# BE-U1000 register map
Vendor: BAIKAL ELECTRONICS, JSC; File version: 1.0
CPU: RISC-V r0p0, little endian, no MPU, no FPU, 3 interrupt priority bits
Registers are 32-bit, read-write, reset 0x0 unless marked. A register's access mark holds for its fields unless they carry their own. Offsets are from the block's base; [hi:lo] are bit positions; {n}, {i} and the like mark numbered series.

## CRU — Control Registers Unit
Base 0x14000000
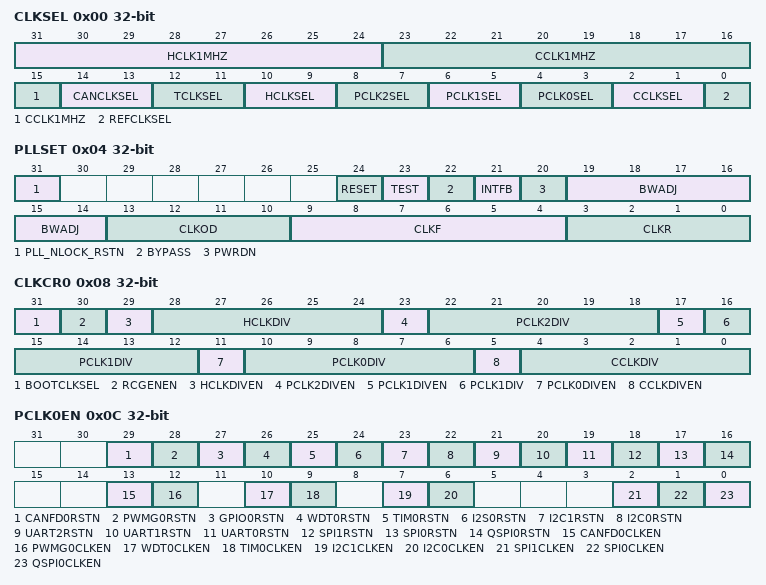
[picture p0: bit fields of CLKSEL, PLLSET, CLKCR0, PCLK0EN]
0x00 CLKSEL — Clock select control
  [31:24] HCLK1MHZ — HCLK 1MHz pulse generator prescaler
  [23:15] CCLK1MHZ — CCLK 1MHz pulse generator prescaler
  [14:13] CANCLKSEL — CANx2 clock (CANx2CLK) source select
    0=C0 (C0 used as CANx2 clock (CANx2CLK) source); 1=PLL (PLL used as CANx2 clock (CANx2CLK) source); 2=C1 (C1 used as CANx2 clock (CANx2CLK) source)
  [12:11] TCLKSEL — TRACE clock (TRACECLK) source select
    0=C0 (C0 used as TRACE clock (TCLK) source); 1=PLL (PLL used as TRACE clock (TCLK) source); 2=C1 (C1 used as TRACE clock (TCLK) source)
  [10:9] HCLKSEL — AHB domain clock (HCLK) source select
    0=C0 (C0 used as AHB domain clock (HCLK) source); 1=PLL (PLL used as AHB domain clock (HCLK) source); 2=C1 (C1 used as AHB domain clock (HCLK) source)
  [8:7] PCLK2SEL — APB2 domain clock (PCLK2) source select
    0=C0 (C0 used as APB2 domain clock (PCLK2) source); 1=PLL (PLL used as APB2 domain clock (PCLK2) source); 2=C1 (C1 used as APB2 domain clock (PCLK2) source)
  [6:5] PCLK1SEL — APB1 domain clock (PCLK1) source select
    0=C0 (C0 used as APB1 domain clock (PCLK1) source); 1=PLL (PLL used as APB1 domain clock (PCLK1) source); 2=C1 (C1 used as APB1 domain clock (PCLK1) source)
  [4:3] PCLK0SEL — APB0 domain clock (PCLK0) source select
    0=C0 (C0 used as APB0 domain clock (PCLK0) source); 1=PLL (PLL used as APB0 domain clock (PCLK0) source); 2=C1 (C1 used as APB0 domain clock (PCLK0) source)
  [2:1] CCLKSEL — AXI domain clock (CCLK) source select
    0=C0 (C0 used as AXI domain clock (CCLK) source); 1=PLL (PLL used as AXI domain clock (CCLK) source); 2=C1 (C1 used as AXI domain clock (CCLK) source)
  [0] REFCLKSEL — PLL clock source select
    0=C0 (C0 selected as PLL clock source); 1=C1 (C1 selected as PLL clock source)
0x04 PLLSET — PLL configuration set
  [31] PLL_NLOCK_RSTN — PLL_NLOCK flag reset
    0=DISABLE; 1=ENABLE
  [24] RESET — PLL reset
    0=DISABLE; 1=ENABLE
  [23] TEST — PLL reference to counters to output bypass
    0=DISABLE; 1=ENABLE
  [22] BYPASS — PLL reference to output bypass
    0=DISABLE; 1=ENABLE
  [21] INTFB — PLL internal feedback path select
    0=DISABLE; 1=ENABLE
  [20] PWRDN — PLL power down
    0=DISABLE; 1=ENABLE
  [19:14] BWADJ — PLL bandwidth divider (NB) value
  [13:10] CLKOD — PLL post VCO divider (OD) value
  [9:4] CLKF — PLL multiplication factor (NF) value
  [3:0] CLKR — PLL reference divider (NR) value
0x08 CLKCR0 — Clock domains select control 0
  [31] BOOTCLKSEL — Boot clock source select
    0=DISABLE; 1=ENABLE
  [30] RCGENEN — RC generator enable
    0=DISABLE; 1=ENABLE
  [29] HCLKDIVEN — HCLK divider enable
    0=DISABLE; 1=ENABLE
  [28:24] HCLKDIV — HCLK divider
    0=DIV1 (HCLK not divided); 2=DIV2 (HCLK divided by 2); 4=DIV3 (HCLK divided by 3); 6=DIV4 (HCLK divided by 4); 8=DIV5 (HCLK divided by 5); 10=DIV6 (HCLK divided by 6); 12=DIV7 (HCLK divided by 7); 14=DIV8 (HCLK divided by 8); 16=DIV9 (HCLK divided by 9); 18=DIV10 (HCLK divided by 10); 20=DIV11 (HCLK divided by 11); 22=DIV12 (HCLK divided by 12); 24=DIV13 (HCLK divided by 13); 26=DIV14 (HCLK divided by 14); 28=DIV15 (HCLK divided by 15); 30=DIV16 (HCLK divided by 16); 1=DIV1_5 (HCLK divided by 1.5); 3=DIV2_5 (HCLK divided by 2.5); 5=DIV3_5 (HCLK divided by 3.5); 7=DIV4_5 (HCLK divided by 4.5); 9=DIV5_5 (HCLK divided by 5.5); 11=DIV6_5 (HCLK divided by 6.5); 13=DIV7_5 (HCLK divided by 7.5); 15=DIV8_5 (HCLK divided by 8.5); 17=DIV9_5 (HCLK divided by 9.5); 19=DIV10_5 (HCLK divided by 10.5); 21=DIV11_5 (HCLK divided by 11.5); 23=DIV12_5 (HCLK divided by 12.5); 25=DIV13_5 (HCLK divided by 13.5); 27=DIV14_5 (HCLK divided by 14.5); 29=DIV15_5 (HCLK divided by 15.5)
  [23] PCLK2DIVEN — PCLK2 divider enable
    0=DISABLE; 1=ENABLE
  [22:18] PCLK2DIV — PCLK2 divider
    0=DIV1 (PCLK2 not divided); 2=DIV2 (PCLK2 divided by 2); 4=DIV3 (PCLK2 divided by 3); 6=DIV4 (PCLK2 divided by 4); 8=DIV5 (PCLK2 divided by 5); 10=DIV6 (PCLK2 divided by 6); 12=DIV7 (PCLK2 divided by 7); 14=DIV8 (PCLK2 divided by 8); 16=DIV9 (PCLK2 divided by 9); 18=DIV10 (PCLK2 divided by 10); 20=DIV11 (PCLK2 divided by 11); 22=DIV12 (PCLK2 divided by 12); 24=DIV13 (PCLK2 divided by 13); 26=DIV14 (PCLK2 divided by 14); 28=DIV15 (PCLK2 divided by 15); 30=DIV16 (PCLK2 divided by 16); 1=DIV1_5 (PCLK2 divided by 1.5); 3=DIV2_5 (PCLK2 divided by 2.5); 5=DIV3_5 (PCLK2 divided by 3.5); 7=DIV4_5 (PCLK2 divided by 4.5); 9=DIV5_5 (PCLK2 divided by 5.5); 11=DIV6_5 (PCLK2 divided by 6.5); 13=DIV7_5 (PCLK2 divided by 7.5); 15=DIV8_5 (PCLK2 divided by 8.5); 17=DIV9_5 (PCLK2 divided by 9.5); 19=DIV10_5 (PCLK2 divided by 10.5); 21=DIV11_5 (PCLK2 divided by 11.5); 23=DIV12_5 (PCLK2 divided by 12.5); 25=DIV13_5 (PCLK2 divided by 13.5); 27=DIV14_5 (PCLK2 divided by 14.5); 29=DIV15_5 (PCLK2 divided by 15.5)
  [17] PCLK1DIVEN — PCLK1 divider enable
    0=DISABLE; 1=ENABLE
  [16:12] PCLK1DIV — PCLK1 divider
    0=DIV1 (PCLK1 not divided); 2=DIV2 (PCLK1 divided by 2); 4=DIV3 (PCLK1 divided by 3); 6=DIV4 (PCLK1 divided by 4); 8=DIV5 (PCLK1 divided by 5); 10=DIV6 (PCLK1 divided by 6); 12=DIV7 (PCLK1 divided by 7); 14=DIV8 (PCLK1 divided by 8); 16=DIV9 (PCLK1 divided by 9); 18=DIV10 (PCLK1 divided by 10); 20=DIV11 (PCLK1 divided by 11); 22=DIV12 (PCLK1 divided by 12); 24=DIV13 (PCLK1 divided by 13); 26=DIV14 (PCLK1 divided by 14); 28=DIV15 (PCLK1 divided by 15); 30=DIV16 (PCLK1 divided by 16); 1=DIV1_5 (PCLK1 divided by 1.5); 3=DIV2_5 (PCLK1 divided by 2.5); 5=DIV3_5 (PCLK1 divided by 3.5); 7=DIV4_5 (PCLK1 divided by 4.5); 9=DIV5_5 (PCLK1 divided by 5.5); 11=DIV6_5 (PCLK1 divided by 6.5); 13=DIV7_5 (PCLK1 divided by 7.5); 15=DIV8_5 (PCLK1 divided by 8.5); 17=DIV9_5 (PCLK1 divided by 9.5); 19=DIV10_5 (PCLK1 divided by 10.5); 21=DIV11_5 (PCLK1 divided by 11.5); 23=DIV12_5 (PCLK1 divided by 12.5); 25=DIV13_5 (PCLK1 divided by 13.5); 27=DIV14_5 (PCLK1 divided by 14.5); 29=DIV15_5 (PCLK1 divided by 15.5)
  [11] PCLK0DIVEN — PCLK0 divider enable
    0=DISABLE; 1=ENABLE
  [10:6] PCLK0DIV — PCLK0 divider
    0=DIV1 (PCLK0 not divided); 2=DIV2 (PCLK0 divided by 2); 4=DIV3 (PCLK0 divided by 3); 6=DIV4 (PCLK0 divided by 4); 8=DIV5 (PCLK0 divided by 5); 10=DIV6 (PCLK0 divided by 6); 12=DIV7 (PCLK0 divided by 7); 14=DIV8 (PCLK0 divided by 8); 16=DIV9 (PCLK0 divided by 9); 18=DIV10 (PCLK0 divided by 10); 20=DIV11 (PCLK0 divided by 11); 22=DIV12 (PCLK0 divided by 12); 24=DIV13 (PCLK0 divided by 13); 26=DIV14 (PCLK0 divided by 14); 28=DIV15 (PCLK0 divided by 15); 30=DIV16 (PCLK0 divided by 16); 1=DIV1_5 (PCLK0 divided by 1.5); 3=DIV2_5 (PCLK0 divided by 2.5); 5=DIV3_5 (PCLK0 divided by 3.5); 7=DIV4_5 (PCLK0 divided by 4.5); 9=DIV5_5 (PCLK0 divided by 5.5); 11=DIV6_5 (PCLK0 divided by 6.5); 13=DIV7_5 (PCLK0 divided by 7.5); 15=DIV8_5 (PCLK0 divided by 8.5); 17=DIV9_5 (PCLK0 divided by 9.5); 19=DIV10_5 (PCLK0 divided by 10.5); 21=DIV11_5 (PCLK0 divided by 11.5); 23=DIV12_5 (PCLK0 divided by 12.5); 25=DIV13_5 (PCLK0 divided by 13.5); 27=DIV14_5 (PCLK0 divided by 14.5); 29=DIV15_5 (PCLK0 divided by 15.5)
  [5] CCLKDIVEN — CCLK divider enable
    0=DISABLE; 1=ENABLE
  [4:0] CCLKDIV — CCLK divider
    0=DIV1 (CCLK not divided); 2=DIV2 (CCLK divided by 2); 4=DIV3 (CCLK divided by 3); 6=DIV4 (CCLK divided by 4); 8=DIV5 (CCLK divided by 5); 10=DIV6 (CCLK divided by 6); 12=DIV7 (CCLK divided by 7); 14=DIV8 (CCLK divided by 8); 16=DIV9 (CCLK divided by 9); 18=DIV10 (CCLK divided by 10); 20=DIV11 (CCLK divided by 11); 22=DIV12 (CCLK divided by 12); 24=DIV13 (CCLK divided by 13); 26=DIV14 (CCLK divided by 14); 28=DIV15 (CCLK divided by 15); 30=DIV16 (CCLK divided by 16); 1=DIV1_5 (CCLK divided by 1.5); 3=DIV2_5 (CCLK divided by 2.5); 5=DIV3_5 (CCLK divided by 3.5); 7=DIV4_5 (CCLK divided by 4.5); 9=DIV5_5 (CCLK divided by 5.5); 11=DIV6_5 (CCLK divided by 6.5); 13=DIV7_5 (CCLK divided by 7.5); 15=DIV8_5 (CCLK divided by 8.5); 17=DIV9_5 (CCLK divided by 9.5); 19=DIV10_5 (CCLK divided by 10.5); 21=DIV11_5 (CCLK divided by 11.5); 23=DIV12_5 (CCLK divided by 12.5); 25=DIV13_5 (CCLK divided by 13.5); 27=DIV14_5 (CCLK divided by 14.5); 29=DIV15_5 (CCLK divided by 15.5)
0x0C PCLK0EN — APB0 domain clock gating control
  [all] fields
    0=DISABLE; 1=ENABLE
  [29] CANFD0RSTN — CANFD0 reset
  [28] PWMG0RSTN — PWMG0 reset
  [27] GPIO0RSTN — GPIO0 reset
  [26] WDT0RSTN — WDT0 reset
  [25] TIM0RSTN — TIM0 reset
  [24] I2S0RSTN — I2S0 reset
  [23] I2C1RSTN — I2C1 reset
  [22] I2C0RSTN — I2C0 reset
  [21] UART2RSTN — UART2 reset
  [20] UART1RSTN — UART1 reset
  [19] UART0RSTN — UART0 reset
  [18] SPI1RSTN — SPI1 reset
  [17] SPI0RSTN — SPI0 reset
  [16] QSPI0RSTN — QSPI0 reset
  [13] CANFD0CLKEN — CANFD0 clock enable
  [12] PWMG0CLKEN — PWMG0 clock enable
  [10] WDT0CLKEN — WDT0 clock enable
  [9] TIM0CLKEN — TIM0 clock enable
  [7] I2C1CLKEN — I2C1 clock enable
  [6] I2C0CLKEN — I2C0 clock enable
  [2] SPI1CLKEN — SPI1 clock enable
  [1] SPI0CLKEN — SPI0 clock enable
  [0] QSPI0CLKEN — QSPI0 clock enable
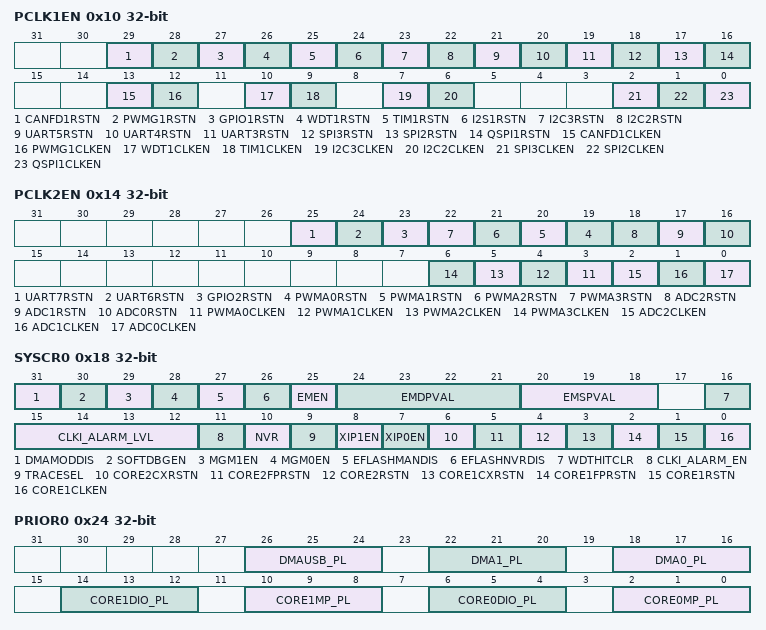
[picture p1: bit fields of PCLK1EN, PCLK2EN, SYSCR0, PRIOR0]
0x10 PCLK1EN — APB1 domain clock gating control
  [all] fields
    0=DISABLE; 1=ENABLE
  [29] CANFD1RSTN — CANFD1 reset
  [28] PWMG1RSTN — PWMG1 reset
  [27] GPIO1RSTN — GPIO1 reset
  [26] WDT1RSTN — WDT1 reset
  [25] TIM1RSTN — TIM1 reset
  [24] I2S1RSTN — I2S1 reset
  [23] I2C3RSTN — I2C3 reset
  [22] I2C2RSTN — I2C2 reset
  [21] UART5RSTN — UART5 reset
  [20] UART4RSTN — UART4 reset
  [19] UART3RSTN — UART3 reset
  [18] SPI3RSTN — SPI3 reset
  [17] SPI2RSTN — SPI2 reset
  [16] QSPI1RSTN — QSPI1 reset
  [13] CANFD1CLKEN — CANFD1 clock enable
  [12] PWMG1CLKEN — PWMG1 clock enable
  [10] WDT1CLKEN — WDT1 clock enable
  [9] TIM1CLKEN — TIM1 clock enable
  [7] I2C3CLKEN — I2C3 clock enable
  [6] I2C2CLKEN — I2C2 clock enable
  [2] SPI3CLKEN — SPI3 clock enable
  [1] SPI2CLKEN — SPI2 clock enable
  [0] QSPI1CLKEN — QSPI1 clock enable
0x14 PCLK2EN — APB2 domain clock gating control
  [all] fields
    0=DISABLE; 1=ENABLE
  [25] UART7RSTN — UART7 reset
  [24] UART6RSTN — UART6 reset
  [23] GPIO2RSTN — GPIO2 reset
  [n+19] PWMA{n}RSTN (n=0..3) — PWMA{n} reset
  [18] ADC2RSTN — ADC2 reset
  [17] ADC1RSTN — ADC1 reset
  [16] ADC0RSTN — ADC0 reset
  [n+3] PWMA{n}CLKEN (n=0..3) — PWMA{n} clock enable
  [2] ADC2CLKEN — ADC2 clock enable
  [1] ADC1CLKEN — ADC1 clock enable
  [0] ADC0CLKEN — ADC0 clock enable
0x18 SYSCR0 — System resource control 0
  [31] DMAMODDIS — Disable write to EFLASH in DMA mode
    0=DISABLE; 1=ENABLE
  [30] SOFTDBGEN — Enable CORE0 and CORE1 software debug
    0=DISABLE; 1=ENABLE
  [29] MGM1EN — MAGMA1 command decryptor enable
    0=DISABLE; 1=ENABLE
  [28] MGM0EN — MAGMA0 command decryptor enable
    0=DISABLE; 1=ENABLE
  [27] EFLASHMANDIS — Disable EFLASH access in manual mode
    0=DISABLE; 1=ENABLE
  [26] EFLASHNVRDIS — Disable EFLASH NVR access
    0=DISABLE; 1=ENABLE
  [25] EMEN — Memory parameters adjustment enable
    0=DISABLE; 1=ENABLE
  [24:21] EMDPVAL — Dual-port memory parameter value
  [20:18] EMSPVAL — Single-port memory parameter value
  [16] WDTHITCLR — Clear WDTHIT flag
    0=DISABLE; 1=ENABLE
  [15:12] CLKI_ALARM_LVL — CLKI monitor threshold
    {v}=CLKI monitor threshold level {v} (v=0..15)
  [11] CLKI_ALARM_EN — CLKI monitor enable
    0=DISABLE; 1=ENABLE
  [10] NVR — EFLASH NVR access enable
    0=DISABLE; 1=ENABLE
  [9] TRACESEL — Select core to trace
    0=CORE0 (Connect Core 0 to trace module); 1=CORE1 (Connect Core 1 to trace module)
  [8] XIP1EN — QSPI1 XIP mode enable
    0=DISABLE; 1=ENABLE
  [7] XIP0EN — QSPI0 XIP mode enable
    0=DISABLE; 1=ENABLE
  [6] CORE2CXRSTN — Core 2 processor complex reset
    0=DISABLE; 1=ENABLE
  [5] CORE2FPRSTN — Core 2 TCM arbitrator reset
    0=DISABLE; 1=ENABLE
  [4] CORE2RSTN — Core 2 reset
    0=DISABLE; 1=ENABLE
  [3] CORE1CXRSTN — Core 1 processor complex reset
    0=DISABLE; 1=ENABLE
  [2] CORE1FPRSTN — Core 1 TCM arbitrator reset
    0=DISABLE; 1=ENABLE
  [1] CORE1RSTN — Core 1 reset
    0=DISABLE; 1=ENABLE
  [0] CORE1CLKEN — Core 1 clock enable
    0=DISABLE; 1=ENABLE
0x1C SYSCR1 — System resource control 1
  [31:0] CORE1RSTVEC — Core 1 reset vector address
0x20 SYSCR2 — System resource control 2
  [31:0] CORE2RSTVEC — Core 2 reset vector address
0x24 PRIOR0 — AXI masters priority control
  [26:24] DMAUSB_PL — USB DMA AXI Interconnect priority level
  [22:20] DMA1_PL — DMA1 AXI Interconnect priority level
  [18:16] DMA0_PL — DMA0 AXI Interconnect priority level
  [14:12] CORE1DIO_PL — DIO Core1 AXI Interconnect priority level
  [10:8] CORE1MP_PL — MP Core1 AXI Interconnect priority level
  [6:4] CORE0DIO_PL — DIO Core0 AXI Interconnect priority level
  [2:0] CORE0MP_PL — MP Core0 AXI Interconnect priority level
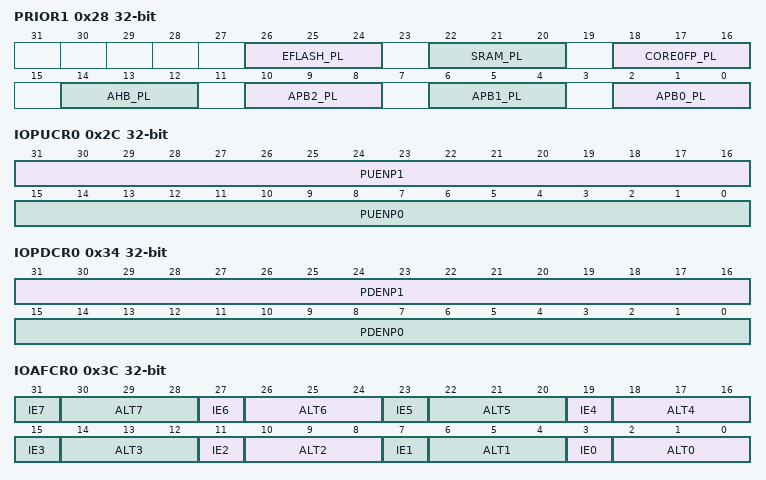
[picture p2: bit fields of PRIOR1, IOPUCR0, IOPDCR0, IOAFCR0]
0x28 PRIOR1 — AXI slave priority control
  [26:24] EFLASH_PL — EFLASH AXI Interconnect priority level
  [22:20] SRAM_PL — SRAM AXI Interconnect priority level
  [18:16] CORE0FP_PL — FP Core0 AXI Interconnect priority level
  [14:12] AHB_PL — AHB AXI Interconnect priority level
  [10:8] APB2_PL — APB2 AXI Interconnect priority level
  [6:4] APB1_PL — APB1 AXI Interconnect priority level
  [2:0] APB0_PL — APB0 AXI Interconnect priority level
0x2C IOPUCR0 — PullUp control 0
  [31:16] PUENP1 — PB[15:0] pull-up enable
  [15:0] PUENP0 — PA[15:0] pull-up enable
0x30 IOPUCR1 — PullUp control 1
  [15:0] PUENP2 — PC[15:0] pull-up enable
0x34 IOPDCR0 — PullDown control 0
  [31:16] PDENP1 — PB[15:0] pull-down enable
  [15:0] PDENP0 — PA[15:0] pull-down enable
0x38 IOPDCR1 — PullDown control 1
  [15:0] PDENP2 — PC[15:0] pull-down enable
0x3C IOAFCR0 — PAD alternate function control 0
  [4n+3] IE{n} (n=0..7) — PA[{n}] pin input enable
    0=DISABLE; 1=ENABLE
  [4n+2:4n] ALT{n} (n=0..7) — PA[{n}] pin alternate function
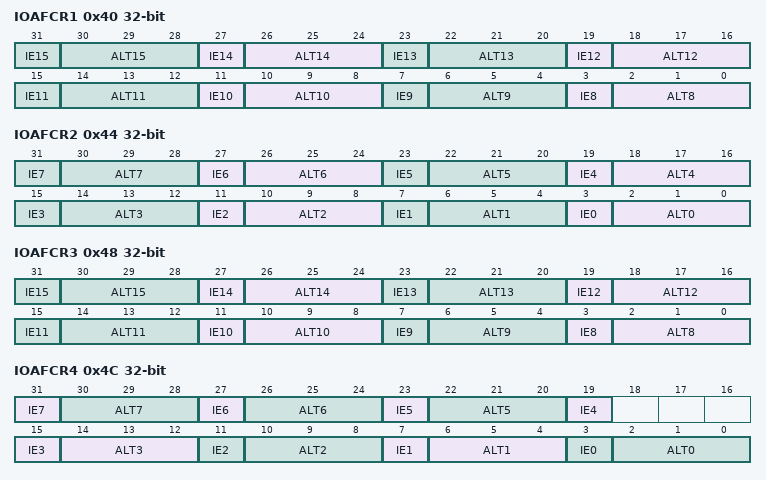
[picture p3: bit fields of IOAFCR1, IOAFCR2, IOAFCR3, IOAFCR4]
0x40 IOAFCR1 — PAD alternate function control 1
  [4n-29] IE{n} (n=8..15) — PA[{n}] pin input enable
    0=DISABLE; 1=ENABLE
  [4n-30:4n-32] ALT{n} (n=8..15) — PA[{n}] pin alternate function
0x44 IOAFCR2 — PAD alternate function control 2
  [4n+3] IE{n} (n=0..7) — PB[{n}] pin input enable
    0=DISABLE; 1=ENABLE
  [4n+2:4n] ALT{n} (n=0..7) — PB[{n}] pin alternate function
0x48 IOAFCR3 — PAD alternate function control 3
  [4n-29] IE{n} (n=8..15) — PB[{n}] pin input enable
    0=DISABLE; 1=ENABLE
  [4n-30:4n-32] ALT{n} (n=8..15) — PB[{n}] pin alternate function
0x4C IOAFCR4 — PAD alternate function control 4
  [31] IE7 — PC[7] pin input enable
    0=DISABLE; 1=ENABLE
  [30:28] ALT7 — PC[7] pin alternate function
  [27] IE6 — PC[6] pin input enable
    0=DISABLE; 1=ENABLE
  [26:24] ALT6 — PC[6] pin alternate function
  [23] IE5 — PC[5] pin input enable
    0=DISABLE; 1=ENABLE
  [22:20] ALT5 — PC[5] pin alternate function
  [19] IE4 — PC[4] pin alternate function
    0=DISABLE; 1=ENABLE
  [4n+3] IE{n} (n=0..3) — PC[{n}] pin input enable
    0=DISABLE; 1=ENABLE
  [4n+2:4n] ALT{n} (n=0..3) — PC[{n}] pin alternate function
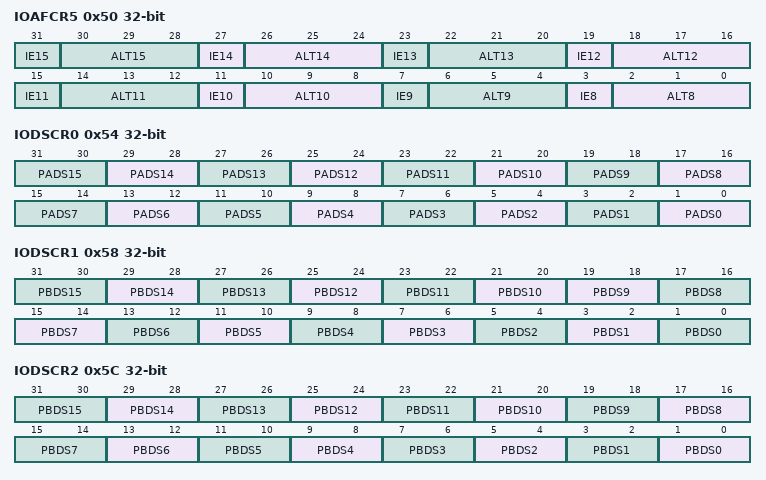
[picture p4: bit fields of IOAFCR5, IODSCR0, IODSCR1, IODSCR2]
0x50 IOAFCR5 — PAD alternate function control 5
  [4n-29] IE{n} (n=8..15) — PC[{n}] pin input enable
    0=DISABLE; 1=ENABLE
  [4n-30:4n-32] ALT{n} (n=8..15) — PC[{n}] pin alternate function
0x54 IODSCR0 — PA outputs drive strength
  [2n+1:2n] PADS{n} (n=0..15) — PA[{n}] output drive mode
0x58 IODSCR1 — PB outputs drive strength
  [2n+1:2n] PBDS{n} (n=10..15) — PB[{n}] output drive mode
  [19:18] PBDS9 — PB[9] output drive
  [2n+1:2n] PBDS{n} (n=0..8) — PB[{n}] output drive mode
0x5C IODSCR2 — PC outputs drive strength
  [2n+1:2n] PBDS{n} (n=0..15) — PC[{n}] output drive mode
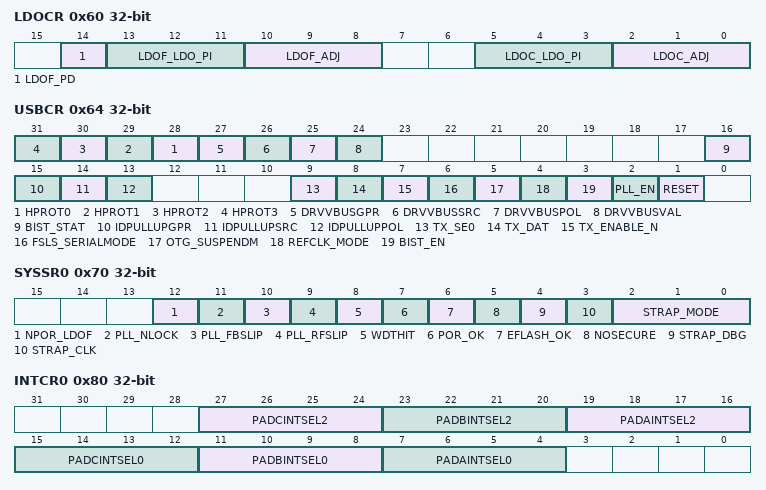
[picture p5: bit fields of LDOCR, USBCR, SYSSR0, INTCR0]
0x60 LDOCR — LDO control register
  [14] LDOF_PD — LDO EFLASH Power Down mode
    0=DISABLE; 1=ENABLE
  [13:11] LDOF_LDO_PI — LDO EFLASH protection current control
    0=LEV0 (LDO EFLASH protection current 290mA); 1=LEV1 (LDO EFLASH protection current 260mA); 2=LEV2 (LDO EFLASH protection current 225mA); 3=LEV3 (LDO EFLASH protection current 195mA); 4=LEV4 (LDO EFLASH protection current 410mA); 5=LEV5 (LDO EFLASH protection current 380mA); 6=LEV6 (LDO EFLASH protection current 350mA); 7=LEV7 (LDO EFLASH protection current 320mA)
  [10:8] LDOF_ADJ — LDO EFLASH output voltage
    0=LEV0 (LDO EFLASH output voltage 1.70V); 1=LEV1 (LDO EFLASH output voltage 1.75V); 2=LEV2 (LDO EFLASH output voltage 1.60V); 3=LEV3 (LDO EFLASH output voltage 1.65V); 4=LEV4 (LDO EFLASH output voltage 1.90V); 5=LEV5 (LDO EFLASH output voltage 1.95V); 6=LEV6 (LDO EFLASH output voltage 0.80V); 7=LEV7 (LDO EFLASH output voltage 0.85V)
  [5:3] LDOC_LDO_PI — LDO CORE protection current control
    0=LEV0 (LDO CORE protection current 500mA); 1=LEV1 (LDO CORE protection current 460mA); 2=LEV2 (LDO CORE protection current 420mA); 3=LEV3 (LDO CORE protection current 380mA); 4=LEV4 (LDO CORE protection current 660mA); 5=LEV5 (LDO CORE protection current 620mA); 6=LEV6 (LDO CORE protection current 580mA)
  [2:0] LDOC_ADJ — LDO CORE output voltage
    0=LEV0 (LDO CORE output voltage 1.10V); 1=LEV1 (LDO CORE output voltage 1.15V); 2=LEV2 (LDO CORE output voltage 1.00V); 3=LEV3 (LDO CORE output voltage 1.05V); 4=LEV4 (LDO CORE output voltage 1.30V); 5=LEV5 (LDO CORE output voltage 1.35V); 6=LEV6 (LDO CORE output voltage 1.20V); 7=LEV7 (LDO CORE output voltage 1.25V)
0x64 USBCR — USB PHY control and status register
  [n+28] HPROT{n} (n=0..3) — HPROT[{n}] from USB controller AHB master
    0=DISABLE; 1=ENABLE
  [27] DRVVBUSGPR — IO control when DRVVBUS alternate function is selected
    0=DISABLE; 1=ENABLE
  [26] DRVVBUSSRC — IO source when DRVVBUS alternate function is selected
    0=DRVVBUS (DRVVBUS output); 1=DRVVBUSGPR (DRVVBUSGPR bit of USBCR register)
  [25] DRVVBUSPOL — IO polarity when DRVVBUS alternate function is selected
    0=NORMAL (Same as DRVVBUS output); 1=INV (Inverted)
  [24] DRVVBUSVAL — IO value when DRVVBUS alternate function is selected
    0=DISABLE (Logical 0); 1=ENABLE (Logical 1)
  [16] BIST_STAT — USB PHY Built-In Self Test (BIST) result
    0=ERROR; 1=SUCCESS
  [15] IDPULLUPGPR — IDPULLUP control
    0=DISABLE; 1=ENABLE
  [14] IDPULLUPSRC — IDPULLUP source
    0=IDPULLUP (IDPULLUP output); 1=IDPULLUPGPR (IDPULLUPGPR bit of USBCR register)
  [13] IDPULLUPPOL — IDPULLUP polarity
    0=NORMAL (Same as IDPULLUP output); 1=INV (Inverted)
  [9] TX_SE0 — USB PHY TX_SE0 control
    0=DISABLE; 1=ENABLE
  [8] TX_DAT — USB PHY TX_DAT control
    0=DISABLE; 1=ENABLE
  [7] TX_ENABLE_N — USB PHY TX_ENABLE_N control
    0=DISABLE; 1=ENABLE
  [6] FSLS_SERIALMODE — USB PHY FSLS_SERIALMODE control
    0=DISABLE; 1=ENABLE
  [5] OTG_SUSPENDM — USB PHY OTG_SUSPENDM control
    0=DISABLE; 1=ENABLE
  [4] REFCLK_MODE — USB PHY REFCLK_MODE control
    0=25MHZ; 1=12MHZ
  [3] BIST_EN — USB PHY Built-In Self Test (BIST) enable
    0=DISABLE; 1=ENABLE
  [2] PLL_EN — USB PHY PLL enable
    0=DISABLE; 1=ENABLE
  [1] RESET — USB PHY reset
    0=DISABLE; 1=ENABLE
0x70 SYSSR0 — System resource status
  [12] NPOR_LDOF — EFLASH LDO NPOR output state
    0=DISABLE; 1=ENABLE
  [11] PLL_NLOCK — PLL NLOCK flag
    0=DISABLE; 1=ENABLE
  [10] PLL_FBSLIP — PLL FBSLIP output state
    0=DISABLE; 1=ENABLE
  [9] PLL_RFSLIP — PLL RFSLIP output state
    0=DISABLE; 1=ENABLE
  [8] WDTHIT — Watchdog reset flag
    0=DISABLE; 1=ENABLE
  [7] POR_OK — POR_OK (PoR circuitry good) input state
    0=DISABLE; 1=ENABLE
  [6] EFLASH_OK — EFLASH_OK (EFLASH good) input state
    0=DISABLE; 1=ENABLE
  [5] NOSECURE — NOSECURE (boot clock source) input state
    0=DISABLE; 1=ENABLE
  [4] STRAP_DBG — Bootstrap inputs state - Debug
    0=EXT (External JTAG); 1=INT (Internal JTAG (CORE2 DEBUG))
  [3] STRAP_CLK — Bootstrap inputs state - Clock
    0=CLKI (CLKI input); 1=RC (RC generator)
  [2:0] STRAP_MODE — Bootstrap inputs state - Mode
    0=EFLASH (EFLASH boot); 1=UART (UART0 boot); 2=QSPI (QSPI0 boot); 3=USB (USB boot); 4=JTAG (JTAG chain); 5=PYTHON (Python boot); 6=MBR (MBR boot)
0x74 WDTCLRKEY — Secure key for WDTx reset
  [31:0] WDTCLRKEY — WDTx reset enable key
0x80 INTCR0 — Interrupt route control
  [27:24] PADCINTSEL2 — PC external interrupt source (CORE2 subsystem)
  [23:20] PADBINTSEL2 — PB external interrupt source (CORE2 subsystem)
  [19:16] PADAINTSEL2 — PA external interrupt source (CORE2 subsystem)
  [15:12] PADCINTSEL0 — PC external interrupt source (CORE0, CORE1 subsystem)
  [11:8] PADBINTSEL0 — PB external interrupt source (CORE0, CORE1 subsystem)
  [7:4] PADAINTSEL0 — PA external interrupt source (CORE0, CORE1 subsystem)
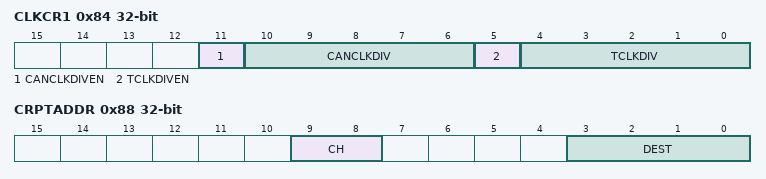
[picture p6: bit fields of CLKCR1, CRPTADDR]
0x84 CLKCR1 — Clock domains select control 1
  [11] CANCLKDIVEN — CANCLK divider enable
    0=DISABLE; 1=ENABLE
  [10:6] CANCLKDIV — CANCLK divider
    0=DIV1 (CANCLK not divided); 2=DIV2 (CANCLK divided by 2); 4=DIV3 (CANCLK divided by 3); 6=DIV4 (CANCLK divided by 4); 8=DIV5 (CANCLK divided by 5); 10=DIV6 (CANCLK divided by 6); 12=DIV7 (CANCLK divided by 7); 14=DIV8 (CANCLK divided by 8); 16=DIV9 (CANCLK divided by 9); 18=DIV10 (CANCLK divided by 10); 20=DIV11 (CANCLK divided by 11); 22=DIV12 (CANCLK divided by 12); 24=DIV13 (CANCLK divided by 13); 26=DIV14 (CANCLK divided by 14); 28=DIV15 (CANCLK divided by 15); 30=DIV16 (CANCLK divided by 16); 1=DIV1_5 (CANCLK divided by 1.5); 3=DIV2_5 (CANCLK divided by 2.5); 5=DIV3_5 (CANCLK divided by 3.5); 7=DIV4_5 (CANCLK divided by 4.5); 9=DIV5_5 (CANCLK divided by 5.5); 11=DIV6_5 (CANCLK divided by 6.5); 13=DIV7_5 (CANCLK divided by 7.5); 15=DIV8_5 (CANCLK divided by 8.5); 17=DIV9_5 (CANCLK divided by 9.5); 19=DIV10_5 (CANCLK divided by 10.5); 21=DIV11_5 (CANCLK divided by 11.5); 23=DIV12_5 (CANCLK divided by 12.5); 25=DIV13_5 (CANCLK divided by 13.5); 27=DIV14_5 (CANCLK divided by 14.5); 29=DIV15_5 (CANCLK divided by 15.5)
  [5] TCLKDIVEN — TCLK divider enable
    0=DISABLE; 1=ENABLE
  [4:0] TCLKDIV — TCLK divider
    0=DIV1 (TCLK not divided); 2=DIV2 (TCLK divided by 2); 4=DIV3 (TCLK divided by 3); 6=DIV4 (TCLK divided by 4); 8=DIV5 (TCLK divided by 5); 10=DIV6 (TCLK divided by 6); 12=DIV7 (TCLK divided by 7); 14=DIV8 (TCLK divided by 8); 16=DIV9 (TCLK divided by 9); 18=DIV10 (TCLK divided by 10); 20=DIV11 (TCLK divided by 11); 22=DIV12 (TCLK divided by 12); 24=DIV13 (TCLK divided by 13); 26=DIV14 (TCLK divided by 14); 28=DIV15 (TCLK divided by 15); 30=DIV16 (TCLK divided by 16); 1=DIV1_5 (TCLK divided by 1.5); 3=DIV2_5 (TCLK divided by 2.5); 5=DIV3_5 (TCLK divided by 3.5); 7=DIV4_5 (TCLK divided by 4.5); 9=DIV5_5 (TCLK divided by 5.5); 11=DIV6_5 (TCLK divided by 6.5); 13=DIV7_5 (TCLK divided by 7.5); 15=DIV8_5 (TCLK divided by 8.5); 17=DIV9_5 (TCLK divided by 9.5); 19=DIV10_5 (TCLK divided by 10.5); 21=DIV11_5 (TCLK divided by 11.5); 23=DIV12_5 (TCLK divided by 12.5); 25=DIV13_5 (TCLK divided by 13.5); 27=DIV14_5 (TCLK divided by 14.5); 29=DIV15_5 (TCLK divided by 15.5)
0x88 CRPTADDR — MAGMA address register
  [9:8] CH — Channel
  [3:0] DEST — Data destination
0x8C CRPTDATA — MAGMA data register
  [31:0] CRPTDATA — Data to be written
0x90 FLASHNVRCR — NVR1 disable register
  [0] FLASHNVRCR — Disable EFLASH NVR Sector 1 modification operations
    0=DISABLE; 1=ENABLE
0x94 CORE1CR — CORE1 presence register
  [0] CORE1CR — CORE1 enable
    0=DISABLE; 1=ENABLE
